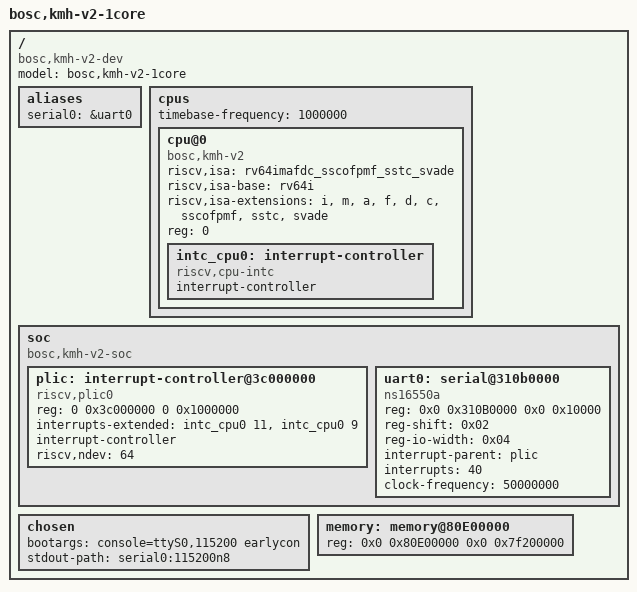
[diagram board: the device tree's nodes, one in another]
// SPDX-License-Identifier: (GPL-2.0 OR MIT)
/* Copyright (c) 2023-2024 BOSC */

/dts-v1/;

/ {
	#address-cells = <2>;
	#size-cells = <2>;
	compatible = "bosc,kmh-v2-dev";
	model = "bosc,kmh-v2-1core";

	aliases {
		serial0 = &uart0;
	};

	cpus {
		#address-cells = <1>;
		#size-cells = <0>;
		timebase-frequency = <1000000>; /* 1Mhz */

		cpu@0 {
			compatible = "bosc,kmh-v2", "riscv";
			device_type = "cpu";
			riscv,isa = "rv64imafdc_sscofpmf_sstc_svade";
			riscv,isa-base = "rv64i";
			riscv,isa-extensions = "i", "m", "a", "f", "d", "c",
					"sscofpmf", "sstc", "svade";
			reg = <0>;

			intc_cpu0: interrupt-controller {
				compatible = "riscv,cpu-intc";
				interrupt-controller;
				#interrupt-cells = <1>;
			};
		};
	};

	soc {
		#address-cells = <2>;
		#size-cells = <2>;
		compatible = "bosc,kmh-v2-soc", "simple-bus";
		ranges;

		plic: interrupt-controller@3c000000 {
			compatible = "riscv,plic0";
			reg = <0 0x3c000000 0 0x1000000>;
			interrupts-extended = <&intc_cpu0 11>, <&intc_cpu0 9>;
			interrupt-controller;
			#address-cells = <0>;
			#interrupt-cells = <1>;
			riscv,ndev = <64>;
		};

		uart0: serial@310b0000 {
			compatible = "ns16550a";
			reg = <0x0 0x310B0000 0x0 0x10000>;
			reg-shift = <0x02>;
			reg-io-width = <0x04>;
			interrupt-parent = <&plic>;
			interrupts = <40>;
			clock-frequency = <50000000>;
		};
	};

	chosen {
		bootargs = "console=ttyS0,115200 earlycon";
		stdout-path = "serial0:115200n8";
	};

	memory: memory@80E00000 {
		device_type = "memory";
		reg = <0x0 0x80E00000 0x0 0x7f200000>;
	};
};
